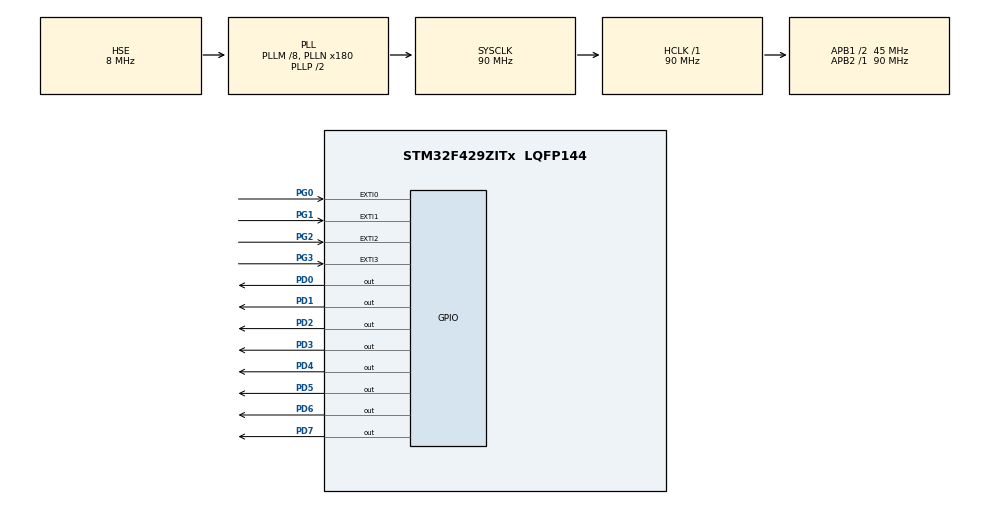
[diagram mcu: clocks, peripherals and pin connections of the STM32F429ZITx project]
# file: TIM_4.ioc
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Mcu.Family=STM32F4
Mcu.Name=STM32F429ZITx
Mcu.Package=LQFP144
NVIC.EXTI0_IRQn=true\:0\:0\:false\:false\:true\:true\:true\:true
NVIC.EXTI1_IRQn=true\:0\:0\:false\:false\:true\:true\:true\:true
NVIC.EXTI2_IRQn=true\:0\:0\:false\:false\:true\:true\:true\:true
NVIC.EXTI3_IRQn=true\:0\:0\:false\:false\:true\:true\:true\:true
NVIC.PriorityGroup=NVIC_PRIORITYGROUP_4
NVIC.RCC_IRQn=true\:0\:0\:false\:false\:true\:true\:false\:true
NVIC.TIM2_IRQn=true\:0\:0\:false\:false\:true\:true\:true\:true
NVIC.TIM4_IRQn=true\:0\:0\:false\:false\:true\:true\:true\:true
PA13.Mode=Serial_Wire
PA13.Signal=SYS_JTMS-SWDIO
PA14.Mode=Serial_Wire
PA14.Signal=SYS_JTCK-SWCLK
PD0.GPIO_ModeDefaultOutputPP=GPIO_MODE_OUTPUT_PP
PD0.GPIO_PuPd=GPIO_PULLUP
PD0.GPIO_Speed=GPIO_SPEED_FREQ_HIGH
PD0.PinState=GPIO_PIN_RESET
PD0.Signal=GPIO_Output
PD1.GPIO_ModeDefaultOutputPP=GPIO_MODE_OUTPUT_PP
PD1.GPIO_PuPd=GPIO_PULLUP
PD1.GPIO_Speed=GPIO_SPEED_FREQ_HIGH
PD1.PinState=GPIO_PIN_RESET
PD1.Signal=GPIO_Output
PD2.GPIO_ModeDefaultOutputPP=GPIO_MODE_OUTPUT_PP
PD2.GPIO_PuPd=GPIO_PULLUP
PD2.GPIO_Speed=GPIO_SPEED_FREQ_HIGH
PD2.PinState=GPIO_PIN_RESET
PD2.Signal=GPIO_Output
PD3.GPIO_ModeDefaultOutputPP=GPIO_MODE_OUTPUT_PP
PD3.GPIO_PuPd=GPIO_PULLUP
PD3.GPIO_Speed=GPIO_SPEED_FREQ_HIGH
PD3.PinState=GPIO_PIN_RESET
PD3.Signal=GPIO_Output
PD4.GPIO_ModeDefaultOutputPP=GPIO_MODE_OUTPUT_PP
PD4.GPIO_PuPd=GPIO_PULLUP
PD4.GPIO_Speed=GPIO_SPEED_FREQ_HIGH
PD4.PinState=GPIO_PIN_RESET
PD4.Signal=GPIO_Output
PD5.GPIO_ModeDefaultOutputPP=GPIO_MODE_OUTPUT_PP
PD5.GPIO_PuPd=GPIO_PULLUP
PD5.GPIO_Speed=GPIO_SPEED_FREQ_HIGH
PD5.PinState=GPIO_PIN_RESET
PD5.Signal=GPIO_Output
PD6.GPIO_ModeDefaultOutputPP=GPIO_MODE_OUTPUT_PP
PD6.GPIO_PuPd=GPIO_PULLUP
PD6.GPIO_Speed=GPIO_SPEED_FREQ_HIGH
PD6.PinState=GPIO_PIN_RESET
PD6.Signal=GPIO_Output
PD7.GPIO_ModeDefaultOutputPP=GPIO_MODE_OUTPUT_PP
PD7.GPIO_PuPd=GPIO_PULLUP
PD7.GPIO_Speed=GPIO_SPEED_FREQ_HIGH
PD7.PinState=GPIO_PIN_RESET
PD7.Signal=GPIO_Output
PG0.GPIO_ModeDefaultEXTI=GPIO_MODE_IT_FALLING
PG0.GPIO_PuPd=GPIO_NOPULL
PG0.Signal=GPXTI0
PG1.GPIO_ModeDefaultEXTI=GPIO_MODE_IT_FALLING
PG1.GPIO_PuPd=GPIO_NOPULL
PG1.Signal=GPXTI1
PG2.GPIO_ModeDefaultEXTI=GPIO_MODE_IT_FALLING
PG2.GPIO_PuPd=GPIO_NOPULL
PG2.Signal=GPXTI2
PG3.GPIO_ModeDefaultEXTI=GPIO_MODE_IT_FALLING
PG3.GPIO_PuPd=GPIO_NOPULL
PG3.Signal=GPXTI3
PH0/OSC_IN.Mode=HSE-External-Clock-Source
PH0/OSC_IN.Signal=RCC_OSC_IN
PH1/OSC_OUT.Mode=HSE-External-Clock-Source
PH1/OSC_OUT.Signal=RCC_OSC_OUT
ProjectManager.HeapSize=0x200
ProjectManager.StackSize=0x400
ProjectManager.TargetToolchain=STM32CubeIDE
RCC.48MHZClocksFreq_Value=45000000
RCC.AHBFreq_Value=90000000
RCC.APB1CLKDivider=RCC_HCLK_DIV2
RCC.APB1Freq_Value=45000000
RCC.APB1TimFreq_Value=90000000
RCC.APB2Freq_Value=90000000
RCC.APB2TimFreq_Value=90000000
RCC.CortexFreq_Value=90000000
RCC.HCLKFreq_Value=90000000
RCC.HSE_VALUE=8000000
RCC.HSI_VALUE=16000000
RCC.LSE_VALUE=32768
RCC.PLLM=8
RCC.PLLN=180
RCC.PLLSourceVirtual=RCC_PLLSOURCE_HSE
RCC.SYSCLKFreq_VALUE=90000000
RCC.SYSCLKSource=RCC_SYSCLKSOURCE_PLLCLK
RCC.VCOOutputFreq_Value=180000000
TIM2.Period=9999
TIM2.Prescaler=8999
TIM4.Channel-Output\ Compare1\ No\ Output=TIM_CHANNEL_1
TIM4.Period=19999
TIM4.Prescaler=8999
TIM4.Pulse-Output\ Compare1\ No\ Output=999
VP_TIM2_VS_ClockSourceINT.Mode=Internal
VP_TIM4_VS_ClockSourceINT.Mode=Internal
VP_TIM4_VS_no_output1.Mode=Output Compare1 No Output
board=custom

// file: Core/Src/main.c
/* USER CODE BEGIN Header */
/**
  ******************************************************************************
  * @file           : main.c
  * @brief          : Main program body
  ******************************************************************************
  * @attention
  *
  * Copyright (c) 2023 STMicroelectronics.
  * All rights reserved.
  *
  * This software is licensed under terms that can be found in the LICENSE file
  * in the root directory of this software component.
  * If no LICENSE file comes with this software, it is provided AS-IS.
  *
  ******************************************************************************
  */
/* USER CODE END Header */
#include "main.h"

TIM_HandleTypeDef htim2;
TIM_HandleTypeDef htim4;

void SystemClock_Config(void);
static void MX_GPIO_Init(void);
static void MX_TIM2_Init(void);
static void MX_TIM4_Init(void);
/* USER CODE BEGIN PFP */

void LED_OnOff(int, int);

/* USER CODE END PFP */

int main(void)
{

  /* MCU Configuration--------------------------------------------------------*/

  /* Reset of all peripherals, Initializes the Flash interface and the Systick. */
  HAL_Init();

  /* Configure the system clock */
  SystemClock_Config();

  /* Initialize all configured peripherals */
  MX_GPIO_Init();
  MX_TIM2_Init();
  MX_TIM4_Init();
  /* USER CODE BEGIN 2 */

  LED_OnOff(LED_ALL, 500);

  HAL_TIM_Base_Start_IT(&htim4);
  HAL_TIM_OC_Start_IT(&htim4, TIM_CHANNEL_1);

  /* USER CODE END 2 */

  /* Infinite loop */
  while (1)
  {

  }
}

void SystemClock_Config(void)
{
  RCC_OscInitTypeDef RCC_OscInitStruct = {0};
  RCC_ClkInitTypeDef RCC_ClkInitStruct = {0};

  /** Configure the main internal regulator output voltage
  */
  __HAL_RCC_PWR_CLK_ENABLE();
  __HAL_PWR_VOLTAGESCALING_CONFIG(PWR_REGULATOR_VOLTAGE_SCALE3);

  /** Initializes the RCC Oscillators according to the specified parameters
  * in the RCC_OscInitTypeDef structure.
  */
  RCC_OscInitStruct.OscillatorType = RCC_OSCILLATORTYPE_HSE;
  RCC_OscInitStruct.HSEState = RCC_HSE_BYPASS;
  RCC_OscInitStruct.PLL.PLLState = RCC_PLL_ON;
  RCC_OscInitStruct.PLL.PLLSource = RCC_PLLSOURCE_HSE;
  RCC_OscInitStruct.PLL.PLLM = 8;
  RCC_OscInitStruct.PLL.PLLN = 180;
  RCC_OscInitStruct.PLL.PLLP = RCC_PLLP_DIV2;
  RCC_OscInitStruct.PLL.PLLQ = 4;
  if (HAL_RCC_OscConfig(&RCC_OscInitStruct) != HAL_OK)
  {
    Error_Handler();
  }

  /** Activate the Over-Drive mode
  */
  if (HAL_PWREx_EnableOverDrive() != HAL_OK)
  {
    Error_Handler();
  }

  /** Initializes the CPU, AHB and APB buses clocks
  */
  RCC_ClkInitStruct.ClockType = RCC_CLOCKTYPE_HCLK|RCC_CLOCKTYPE_SYSCLK
                              |RCC_CLOCKTYPE_PCLK1|RCC_CLOCKTYPE_PCLK2;
  RCC_ClkInitStruct.SYSCLKSource = RCC_SYSCLKSOURCE_PLLCLK;
  RCC_ClkInitStruct.AHBCLKDivider = RCC_SYSCLK_DIV1;
  RCC_ClkInitStruct.APB1CLKDivider = RCC_HCLK_DIV2;
  RCC_ClkInitStruct.APB2CLKDivider = RCC_HCLK_DIV1;

  if (HAL_RCC_ClockConfig(&RCC_ClkInitStruct, FLASH_LATENCY_2) != HAL_OK)
  {
    Error_Handler();
  }
}

static void MX_TIM2_Init(void)
{

  TIM_ClockConfigTypeDef sClockSourceConfig = {0};
  TIM_MasterConfigTypeDef sMasterConfig = {0};

  htim2.Instance = TIM2;
  htim2.Init.Prescaler = 8999;
  htim2.Init.CounterMode = TIM_COUNTERMODE_UP;
  htim2.Init.Period = 9999;
  htim2.Init.ClockDivision = TIM_CLOCKDIVISION_DIV1;
  htim2.Init.AutoReloadPreload = TIM_AUTORELOAD_PRELOAD_DISABLE;
  if (HAL_TIM_Base_Init(&htim2) != HAL_OK)
  {
    Error_Handler();
  }
  sClockSourceConfig.ClockSource = TIM_CLOCKSOURCE_INTERNAL;
  if (HAL_TIM_ConfigClockSource(&htim2, &sClockSourceConfig) != HAL_OK)
  {
    Error_Handler();
  }
  sMasterConfig.MasterOutputTrigger = TIM_TRGO_RESET;
  sMasterConfig.MasterSlaveMode = TIM_MASTERSLAVEMODE_DISABLE;
  if (HAL_TIMEx_MasterConfigSynchronization(&htim2, &sMasterConfig) != HAL_OK)
  {
    Error_Handler();
  }

}

static void MX_TIM4_Init(void)
{

  TIM_ClockConfigTypeDef sClockSourceConfig = {0};
  TIM_MasterConfigTypeDef sMasterConfig = {0};
  TIM_OC_InitTypeDef sConfigOC = {0};

  htim4.Instance = TIM4;
  htim4.Init.Prescaler = 8999;
  htim4.Init.CounterMode = TIM_COUNTERMODE_UP;
  htim4.Init.Period = 19999;
  htim4.Init.ClockDivision = TIM_CLOCKDIVISION_DIV1;
  htim4.Init.AutoReloadPreload = TIM_AUTORELOAD_PRELOAD_DISABLE;
  if (HAL_TIM_Base_Init(&htim4) != HAL_OK)
  {
    Error_Handler();
  }
  sClockSourceConfig.ClockSource = TIM_CLOCKSOURCE_INTERNAL;
  if (HAL_TIM_ConfigClockSource(&htim4, &sClockSourceConfig) != HAL_OK)
  {
    Error_Handler();
  }
  if (HAL_TIM_OC_Init(&htim4) != HAL_OK)
  {
    Error_Handler();
  }
  sMasterConfig.MasterOutputTrigger = TIM_TRGO_RESET;
  sMasterConfig.MasterSlaveMode = TIM_MASTERSLAVEMODE_DISABLE;
  if (HAL_TIMEx_MasterConfigSynchronization(&htim4, &sMasterConfig) != HAL_OK)
  {
    Error_Handler();
  }
  sConfigOC.OCMode = TIM_OCMODE_TIMING;
  sConfigOC.Pulse = 999;
  sConfigOC.OCPolarity = TIM_OCPOLARITY_HIGH;
  sConfigOC.OCFastMode = TIM_OCFAST_DISABLE;
  if (HAL_TIM_OC_ConfigChannel(&htim4, &sConfigOC, TIM_CHANNEL_1) != HAL_OK)
  {
    Error_Handler();
  }

}

static void MX_GPIO_Init(void)
{
  GPIO_InitTypeDef GPIO_InitStruct = {0};

  /* GPIO Ports Clock Enable */
  __HAL_RCC_GPIOH_CLK_ENABLE();
  __HAL_RCC_GPIOG_CLK_ENABLE();
  __HAL_RCC_GPIOA_CLK_ENABLE();
  __HAL_RCC_GPIOD_CLK_ENABLE();

  /*Configure GPIO pin Output Level */
  HAL_GPIO_WritePin(GPIOD, GPIO_PIN_0|GPIO_PIN_1|GPIO_PIN_2|GPIO_PIN_3
                          |GPIO_PIN_4|GPIO_PIN_5|GPIO_PIN_6|GPIO_PIN_7, GPIO_PIN_RESET);

  /*Configure GPIO pins : PG0 PG1 PG2 PG3 */
  GPIO_InitStruct.Pin = GPIO_PIN_0|GPIO_PIN_1|GPIO_PIN_2|GPIO_PIN_3;
  GPIO_InitStruct.Mode = GPIO_MODE_IT_FALLING;
  GPIO_InitStruct.Pull = GPIO_NOPULL;
  HAL_GPIO_Init(GPIOG, &GPIO_InitStruct);

  /*Configure GPIO pins : PD0 PD1 PD2 PD3
                           PD4 PD5 PD6 PD7 */
  GPIO_InitStruct.Pin = GPIO_PIN_0|GPIO_PIN_1|GPIO_PIN_2|GPIO_PIN_3
                          |GPIO_PIN_4|GPIO_PIN_5|GPIO_PIN_6|GPIO_PIN_7;
  GPIO_InitStruct.Mode = GPIO_MODE_OUTPUT_PP;
  GPIO_InitStruct.Pull = GPIO_PULLUP;
  GPIO_InitStruct.Speed = GPIO_SPEED_FREQ_HIGH;
  HAL_GPIO_Init(GPIOD, &GPIO_InitStruct);

  /* EXTI interrupt init*/
  HAL_NVIC_SetPriority(EXTI0_IRQn, 0, 0);
  HAL_NVIC_EnableIRQ(EXTI0_IRQn);

  HAL_NVIC_SetPriority(EXTI1_IRQn, 0, 0);
  HAL_NVIC_EnableIRQ(EXTI1_IRQn);

  HAL_NVIC_SetPriority(EXTI2_IRQn, 0, 0);
  HAL_NVIC_EnableIRQ(EXTI2_IRQn);

  HAL_NVIC_SetPriority(EXTI3_IRQn, 0, 0);
  HAL_NVIC_EnableIRQ(EXTI3_IRQn);

}

/* USER CODE BEGIN 4 */

void LED_OnOff(int led, int interval)
{
	HAL_GPIO_WritePin(GPIO_LED, led, GPIO_PIN_SET );
	HAL_GPIO_WritePin(GPIO_LED_Nucleo, led, GPIO_PIN_SET );
	HAL_Delay(interval);
	HAL_GPIO_WritePin(GPIO_LED, led, GPIO_PIN_RESET );
	HAL_GPIO_WritePin(GPIO_LED_Nucleo, led, GPIO_PIN_RESET );
}
void HAL_TIM_PeriodElapsedCallback(TIM_HandleTypeDef *htim)
{
	if ( htim->Instance == TIM4) HAL_GPIO_WritePin(GPIO_LED, LED_ALL, GPIO_PIN_SET);
}
void HAL_TIM_OC_DelayElapsedCallback(TIM_HandleTypeDef *htim)
{
	if ( htim->Instance == TIM4) HAL_GPIO_WritePin(GPIO_LED, LED_ALL, GPIO_PIN_RESET);
}

/* USER CODE END 4 */

void Error_Handler(void)
{
  __disable_irq();
  while (1)
  {
  }
}
